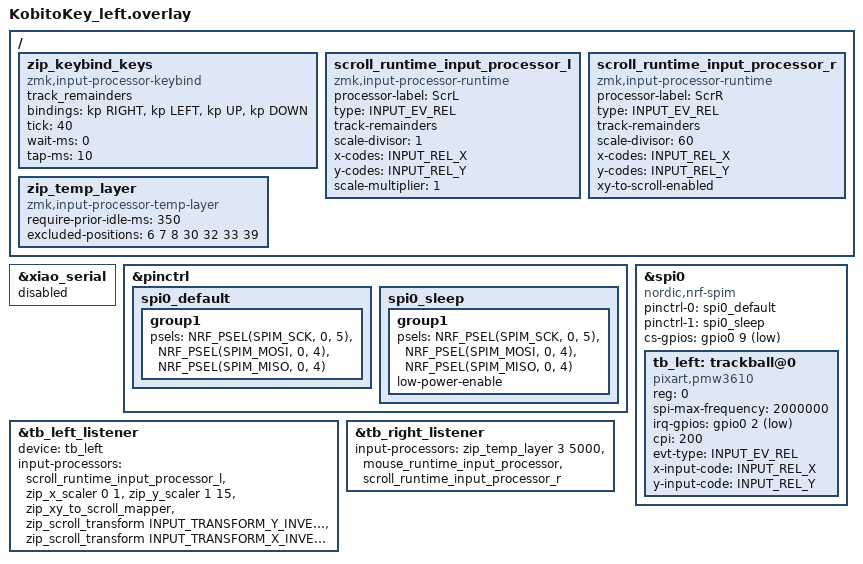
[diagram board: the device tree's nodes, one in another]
#include "kobitokey.dtsi"
#include <zephyr/dt-bindings/input/input-event-codes.h>
#include <dt-bindings/zmk/keys.h>
#include <input/processors.dtsi>
#include <input/processors/sensor_rotation.dtsi>
#include <input/processors/runtime-input-processor.dtsi>

&xiao_serial { status = "disabled"; };

&pinctrl {
    spi0_default: spi0_default {
        group1 {
            psels = <NRF_PSEL(SPIM_SCK,  0, 5)>,
                    <NRF_PSEL(SPIM_MOSI, 0, 4)>,
                    <NRF_PSEL(SPIM_MISO, 0, 4)>;
        };
    };
    spi0_sleep: spi0_sleep {
        group1 {
            psels = <NRF_PSEL(SPIM_SCK,  0, 5)>,
                    <NRF_PSEL(SPIM_MOSI, 0, 4)>,
                    <NRF_PSEL(SPIM_MISO, 0, 4)>;
            low-power-enable;
        };
    };
};

&spi0 {
    status = "okay";
    compatible = "nordic,nrf-spim";
    pinctrl-0 = <&spi0_default>;
    pinctrl-1 = <&spi0_sleep>;
    pinctrl-names = "default", "sleep";
    cs-gpios = <&gpio0 9 GPIO_ACTIVE_LOW>;

    tb_left: trackball@0 {
        status = "okay";
        compatible = "pixart,pmw3610";
        reg = <0>;
        spi-max-frequency = <2000000>;
        irq-gpios = <&gpio0 2 (GPIO_ACTIVE_LOW | GPIO_PULL_UP)>;
        cpi = <200>; /* センサー感度 */


        evt-type = <INPUT_EV_REL>;
        x-input-code = <INPUT_REL_X>;
        y-input-code = <INPUT_REL_Y>;
    };
};

/ {
    zip_keybind_keys: zip_keybind_keys {
        compatible = "zmk,input-processor-keybind";
        #input-processor-cells = <0>;
        track_remainders;
        bindings = <&kp RIGHT>,
                   <&kp LEFT>,
                   <&kp UP>,
                   <&kp DOWN>;
        tick = <40>;
        wait-ms = <0>;
        tap-ms = <10>;
    };

    scroll_runtime_input_processor_l: scroll_runtime_input_processor_l {
		compatible = "zmk,input-processor-runtime";
        processor-label = "ScrL";
		type = <INPUT_EV_REL>;
		track-remainders;
		scale-divisor = <60>;
		#input-processor-cells = <0>;
	}; 

    scroll_runtime_input_processor_r: scroll_runtime_input_processor_r {
		compatible = "zmk,input-processor-runtime";
        processor-label = "ScrR";
		type = <INPUT_EV_REL>;
		track-remainders;
		scale-divisor = <60>;
		#input-processor-cells = <0>;
	}; 
};

&tb_left_listener {
    status = "okay";
    device = <&tb_left>;

    input-processors =
        <&scroll_runtime_input_processor_l>,
        <&zip_x_scaler 0 1>,
        <&zip_y_scaler 1 15>,
        <&zip_xy_to_scroll_mapper>,
        <&zip_scroll_transform INPUT_TRANSFORM_Y_INVERT>,
        <&zip_scroll_transform INPUT_TRANSFORM_X_INVERT>;
};

/ {
    /omit-if-no-ref/ zip_temp_layer: zip_temp_layer {
        compatible = "zmk,input-processor-temp-layer";
        #input-processor-cells = <2>;
        require-prior-idle-ms = <350>;
    };
};

&tb_right_listener {
    status = "okay";

    input-processors =
        <&zip_temp_layer 3 5000>,
        <&mouse_runtime_input_processor &scroll_runtime_input_processor_r>;
};
&zip_temp_layer {
    excluded-positions = <
        6
        7
        8
        30
        32
        33
        39
    >;
};

&scroll_runtime_input_processor_l {
    processor-label = "ScrL";
    x-codes = <INPUT_REL_X>;
    y-codes = <INPUT_REL_Y>;
    scale-multiplier = <1>;
    scale-divisor = <1>;
};

&scroll_runtime_input_processor_r {
        processor-label = "ScrR";
        x-codes = <INPUT_REL_X>;
        y-codes = <INPUT_REL_Y>;
        xy-to-scroll-enabled;
};
